# FM33FK5XX register map
File version: 1.0
CPU: Cortex-M33 r1p0, little endian, MPU, FPU, 3 interrupt priority bits
Registers are 32-bit, read-write, reset 0x0 unless marked. A register's access mark holds for its fields unless they carry their own. Offsets are from the block's base; [hi:lo] are bit positions; {n}, {i} and the like mark numbered series.

## BSTIM16 — BSTIM16 module information
Base 0x4001B400
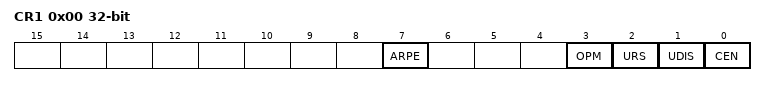
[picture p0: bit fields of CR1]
0x00 CR1 — BSTIM16ControlRegister1
  [7] ARPE — ARPE field description
  [3] OPM — OPM field description
  [2] URS — URS field description
  [1] UDIS — UDIS field description
  [0] CEN — CEN field description
0x04 CR2 — BSTIM16ControlRegister2
  [6:4] MMS — MMS field description
0x0C IER — BSTIM16InterruptEnableRegister
  [0] UIE — UIE field description
0x10 ISR — BSTIM16InterruptStatusRegister
  [0] UIF — UIF field description
0x14 EGR wo — BSTIM16EventGenerationRegister
  [0] UG — UG field description
0x24 CNT — BSTIM16CounterRegister
  [15:0] CNT — CNT field description
0x28 PSC — BSTIM16PrescalerRegister
  [15:0] PSC — PSC field description
0x2C ARR reset 0xFFFF — BSTIM16Auto-ReloadRegister
  [15:0] ARR — ARR field description

## LPTIM16 — LPTIM16 module information
Base 0x40020000
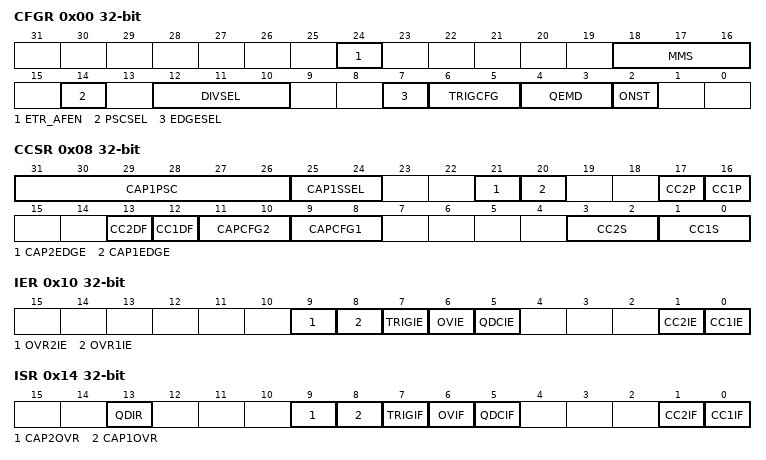
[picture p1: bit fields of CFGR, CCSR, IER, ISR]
0x00 CFGR — LPTIM16ConfigRegister
  [24] ETR_AFEN — ETR_AFEN field description
  [18:16] MMS — MMS field description
  [14] PSCSEL — PSCSEL field description
  [12:10] DIVSEL — DIVSEL field description
  [7] EDGESEL — EDGESEL field description
  [6:5] TRIGCFG — TRIGCFG field description
  [4:3] QEMD — QEMD field description
  [2] ONST — ONST field description
0x04 CNT ro — LPTIM16CounterRegister
  [15:0] CNT16 — CNT16 field description
0x08 CCSR access per field — LPTIM16Capture/CompareControlandStatusRegister
  [31:26] CAP1PSC rw — CAP1PSC field description
  [25:24] CAP1SSEL rw — CAP1SSEL field description
  [21] CAP2EDGE ro — CAP2EDGE field description
  [20] CAP1EDGE ro — CAP1EDGE field description
  [17] CC2P rw — CC2P field description
  [16] CC1P rw — CC1P field description
  [13] CC2DF rw — CC2DF field description
  [12] CC1DF rw — CC1DF field description
  [11:10] CAPCFG2 rw — CAPCFG2 field description
  [9:8] CAPCFG1 rw — CAPCFG1 field description
  [3:2] CC2S rw — CC2S field description
  [1:0] CC1S rw — CC1S field description
0x0C ARR — LPTIM16Auto-ReloadRegister
  [15:0] ARR — ARR field description
0x10 IER — LPTIM16InterruptEnableRegister
  [9] OVR2IE — OVR2IE field description
  [8] OVR1IE — OVR1IE field description
  [7] TRIGIE — TRIGIE field description
  [6] OVIE — OVIE field description
  [5] QDCIE — QDCIE field description
  [1] CC2IE — CC2IE field description
  [0] CC1IE — CC1IE field description
0x14 ISR access per field — LPTIM16InterruptStatusRegister
  [13] QDIR ro — QDIR field description
  [9] CAP2OVR rw — CAP2OVR field description
  [8] CAP1OVR rw — CAP1OVR field description
  [7] TRIGIF rw — TRIGIF field description
  [6] OVIF rw — OVIF field description
  [5] QDCIF rw — QDCIF field description
  [1] CC2IF rw — CC2IF field description
  [0] CC1IF rw — CC1IF field description
0x18 CR — LPTIM16ControlRegister
  [0] EN — EN field description
0x20 CCR1 — LPTIM16Capture/CompareRegister1
  [15:0] CCR1 — CCR1 field description
0x24 CCR2 — LPTIM16Capture/CompareRegister2
  [15:0] CCR2 — CCR2 field description

## RTCB — RTCB module information
Base 0x4001F000
0x00 WER
  [0] RTCWE — RTCWE field description
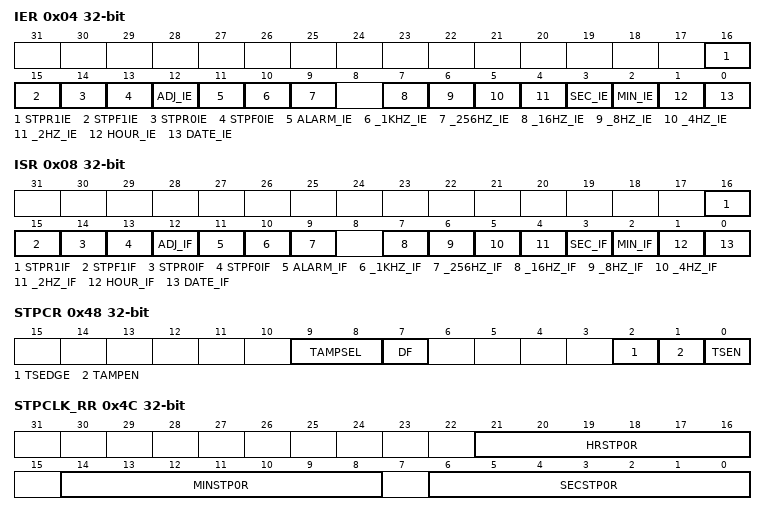
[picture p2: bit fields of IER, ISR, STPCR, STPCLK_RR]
0x04 IER
  [16] STPR1IE — STPR1IE field description
  [15] STPF1IE — STPF1IE field description
  [14] STPR0IE — STPR0IE field description
  [13] STPF0IE — STPF0IE field description
  [12] ADJ_IE — ADJ_IE field description
  [11] ALARM_IE — ALARM_IE field description
  [10] _1KHZ_IE — _1KHZ_IE field description
  [9] _256HZ_IE — _256HZ_IE field description
  [7] _16HZ_IE — _16HZ_IE field description
  [6] _8HZ_IE — _8HZ_IE field description
  [5] _4HZ_IE — _4HZ_IE field description
  [4] _2HZ_IE — _2HZ_IE field description
  [3] SEC_IE — SEC_IE field description
  [2] MIN_IE — MIN_IE field description
  [1] HOUR_IE — HOUR_IE field description
  [0] DATE_IE — DATE_IE field description
0x08 ISR
  [16] STPR1IF — STPR1IF field description
  [15] STPF1IF — STPF1IF field description
  [14] STPR0IF — STPR0IF field description
  [13] STPF0IF — STPF0IF field description
  [12] ADJ_IF — ADJ_IF field description
  [11] ALARM_IF — ALARM_IF field description
  [10] _1KHZ_IF — _1KHZ_IF field description
  [9] _256HZ_IF — _256HZ_IF field description
  [7] _16HZ_IF — _16HZ_IF field description
  [6] _8HZ_IF — _8HZ_IF field description
  [5] _4HZ_IF — _4HZ_IF field description
  [4] _2HZ_IF — _2HZ_IF field description
  [3] SEC_IF — SEC_IF field description
  [2] MIN_IF — MIN_IF field description
  [1] HOUR_IF — HOUR_IF field description
  [0] DATE_IF — DATE_IF field description
0x0C BCDSEC
  [6:0] BCDSEC — BCDSEC field description
0x10 BCDMIN
  [6:0] BCDMIN — BCDMIN field description
0x14 BCDHOUR
  [5:0] BCDHOUR — BCDHOUR field description
0x1C BCDWEEK
  [2:0] BCDWEEK — BCDWEEK field description
0x20 BCDMONTH
  [4:0] BCDMONTH — BCDMONTH field description
0x24 BCDYEAR
  [7:0] BCDYEAR — BCDYEAR field description
0x2C FSEL
  [3:0] FSEL — FSEL field description
0x30 ADJUST
  [12:0] ADJUST — ADJUST field description
0x40 CR reset 0x1
  [0] EN — EN field description
0x48 STPCR
  [9:8] TAMPSEL — TAMPSEL field description
  [7] DF — DF field description
  [2] TSEDGE — TSEDGE field description
  [1] TAMPEN — TAMPEN field description
  [0] TSEN — TSEN field description
0x4C STPCLK_RR
  [21:16] HRSTP0R — HRSTP0R field description
  [14:8] MINSTP0R — MINSTP0R field description
  [6:0] SECSTP0R — SECSTP0R field description
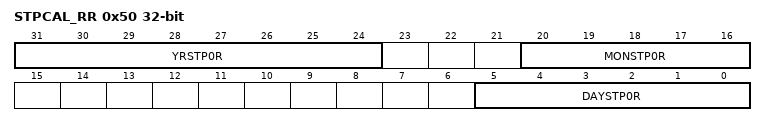
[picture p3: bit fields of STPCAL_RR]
0x50 STPCAL_RR
  [31:24] YRSTP0R — YRSTP0R field description
  [20:16] MONSTP0R — MONSTP0R field description
  [5:0] DAYSTP0R — DAYSTP0R field description
{0x70+4i} BKR{i} (i=0..4)
  [31:0] BKP — BKP field description
